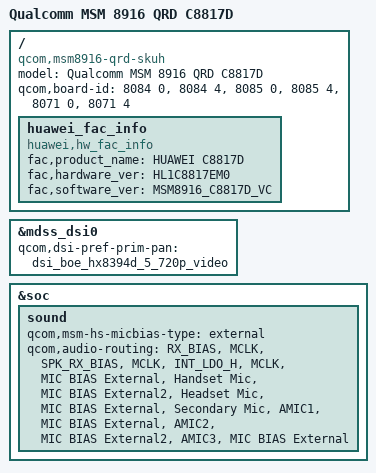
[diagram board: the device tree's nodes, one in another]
/* Copyright (c) 2014, The Linux Foundation. All rights reserved.
 *
 * This program is free software; you can redistribute it and/or modify
 * it under the terms of the GNU General Public License version 2 and
 * only version 2 as published by the Free Software Foundation.
 *
 * This program is distributed in the hope that it will be useful,
 * but WITHOUT ANY WARRANTY; without even the implied warranty of
 * MERCHANTABILITY or FITNESS FOR A PARTICULAR PURPOSE.  See the
 * GNU General Public License for more details.
 */

/dts-v1/;

#include "msm8916-qrd.dtsi"
#include "msm8916-memory.dtsi"
#include "c8817d/msm8916-qrd-c8817d.dtsi"

/ {
	model = "Qualcomm MSM 8916 QRD C8817D";
	compatible = "qcom,msm8916-qrd-skuh", "qcom,msm8916-qrd", "qcom,msm8916", "qcom,qrd";
	qcom,board-id = <8084 0>, <8084 4>,
			<8085 0>, <8085 4>,
			<8071 0>, <8071 4>;
};

&mdss_dsi0 {
	qcom,dsi-pref-prim-pan = <&dsi_boe_hx8394d_5_720p_video>;
};

&soc {

	sound {
		qcom,msm-hs-micbias-type = "external";
		qcom,audio-routing =
				"RX_BIAS", "MCLK",
				"SPK_RX_BIAS", "MCLK",
				"INT_LDO_H", "MCLK",
				"MIC BIAS External", "Handset Mic",
				"MIC BIAS External2", "Headset Mic",
				"MIC BIAS External", "Secondary Mic",
				"AMIC1", "MIC BIAS External",
				"AMIC2", "MIC BIAS External2",
				"AMIC3", "MIC BIAS External";
	};
};

/ {
	huawei_fac_info {
		compatible = "huawei,hw_fac_info";
		fac,product_name = "HUAWEI C8817D";
		fac,hardware_ver = "HL1C8817EM0";
		fac,software_ver = "MSM8916_C8817D_VC";
		status = "ok";
	};
};
